# PIC16LF1776 register map
Vendor: Microchip
Registers are 8-bit, read-write, reset 0x0 unless marked. A register's access mark holds for its fields unless they carry their own. Addresses are absolute, and some are shared; only a register's first bit layout is shown; [hi:lo] are bit positions; {n}, {i} and the like mark numbered series; 'fields as' and 'values as' point back to an identical list.

## pwm
0x614 PWM3DCL reset not defined — (power-on value xx------)
  [7:6] DC
0x615 PWM3DCH reset not defined — (power-on value xxxxxxxx)
  [7:0] DC
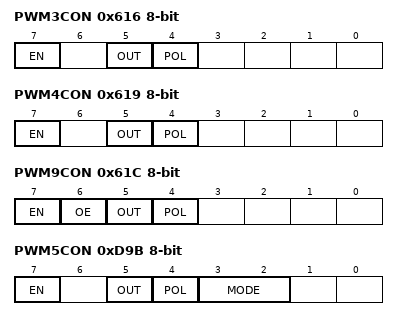
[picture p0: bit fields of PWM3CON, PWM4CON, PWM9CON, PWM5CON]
0x616 PWM3CON
  [7] EN, [5] OUT ro, [4] POL
0x617 PWM4DCL reset not defined — (power-on value xx------)
  [7:6] DC
0x618 PWM4DCH reset not defined — (power-on value xxxxxxxx)
  [7:0] DC
0x619 PWM4CON
  [7] EN, [5] OUT ro, [4] POL
0x61A PWM9DCL reset not defined — (power-on value xx------)
  [7:6] DC
0x61B PWM9DCH reset not defined — (power-on value xxxxxxxx)
  [7:0] DC
0x61C PWM9CON
  [7] EN, [6] OE, [5] OUT ro, [4] POL
0xD91 PWM5PHL reset not defined — 8-bit period timer (power-on value xxxxxxxx)
  [7:0] PH
0xD92 PWM5PHH reset not defined — (power-on value xxxxxxxx)
  [7:0] PH
0xD93 PWM5DCL reset not defined — (power-on value xxxxxxxx)
  [7:0] DC
0xD94 PWM5DCH reset not defined — (power-on value xxxxxxxx)
  [7:0] DC
0xD95 PWM5PRL reset not defined — (power-on value xxxxxxxx)
  [7:0] PR
0xD96 PWM5PRH reset not defined — (power-on value xxxxxxxx)
  [7:0] PR
0xD97 PWM5OFL reset not defined — (power-on value xxxxxxxx)
  [7:0] OF
0xD98 PWM5OFH reset not defined — (power-on value xxxxxxxx)
  [7:0] OF
0xD99 PWM5TMRL
  [7:0] TMR
0xD9A PWM5TMRH
  [7:0] TMR
0xD9B PWM5CON
  [7] EN, [5] OUT ro, [4] POL, [3:2] MODE
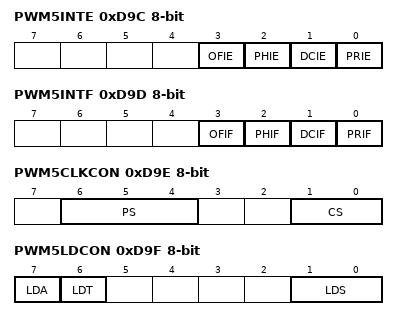
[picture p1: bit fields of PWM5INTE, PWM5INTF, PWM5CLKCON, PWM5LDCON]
0xD9C PWM5INTE
  [3] OFIE, [2] PHIE, [1] DCIE, [0] PRIE
0xD9D PWM5INTF
  [3] OFIF — (can only be cleared)
  [2] PHIF — (can only be cleared)
  [1] DCIF — (can only be cleared)
  [0] PRIF — (can only be cleared)
0xD9E PWM5CLKCON
  [6:4] PS, [1:0] CS
0xD9F PWM5LDCON
  [7] LDA, [6] LDT, [1:0] LDS
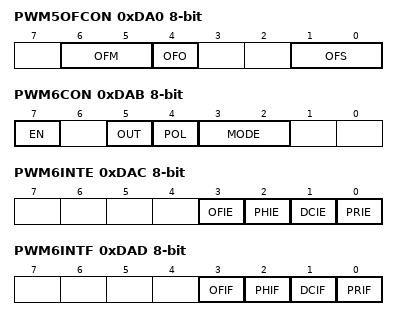
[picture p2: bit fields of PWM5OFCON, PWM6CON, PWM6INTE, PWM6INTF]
0xDA0 PWM5OFCON
  [6:5] OFM, [4] OFO, [1:0] OFS
0xDA1 PWM6PHL reset not defined — 8-bit period timer (power-on value xxxxxxxx)
  [7:0] PH
0xDA2 PWM6PHH reset not defined — (power-on value xxxxxxxx)
  [7:0] PH
0xDA3 PWM6DCL reset not defined — (power-on value xxxxxxxx)
  [7:0] DC
0xDA4 PWM6DCH reset not defined — (power-on value xxxxxxxx)
  [7:0] DC
0xDA5 PWM6PRL reset not defined — (power-on value xxxxxxxx)
  [7:0] PR
0xDA6 PWM6PRH reset not defined — (power-on value xxxxxxxx)
  [7:0] PR
0xDA7 PWM6OFL reset not defined — (power-on value xxxxxxxx)
  [7:0] OF
0xDA8 PWM6OFH reset not defined — (power-on value xxxxxxxx)
  [7:0] OF
0xDA9 PWM6TMRL
  [7:0] TMR
0xDAA PWM6TMRH
  [7:0] TMR
0xDAB PWM6CON
  [7] EN, [5] OUT ro, [4] POL, [3:2] MODE
0xDAC PWM6INTE
  [3] OFIE, [2] PHIE, [1] DCIE, [0] PRIE
0xDAD PWM6INTF
  fields as PWM5INTF
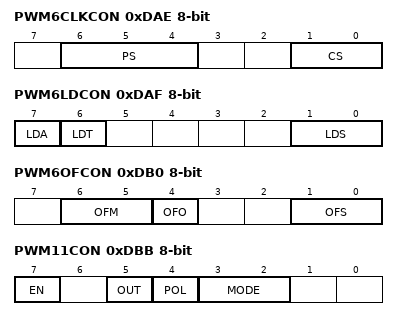
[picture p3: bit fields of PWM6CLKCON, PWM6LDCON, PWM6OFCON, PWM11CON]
0xDAE PWM6CLKCON
  [6:4] PS, [1:0] CS
0xDAF PWM6LDCON
  [7] LDA, [6] LDT, [1:0] LDS
0xDB0 PWM6OFCON
  [6:5] OFM, [4] OFO, [1:0] OFS
0xDB1 PWM11PHL reset not defined — 8-bit period timer (power-on value xxxxxxxx)
  [7:0] PH
0xDB2 PWM11PHH reset not defined — (power-on value xxxxxxxx)
  [7:0] PH
0xDB3 PWM11DCL reset not defined — (power-on value xxxxxxxx)
  [7:0] DC
0xDB4 PWM11DCH reset not defined — (power-on value xxxxxxxx)
  [7:0] DC
0xDB5 PWM11PRL reset not defined — (power-on value xxxxxxxx)
  [7:0] PR
0xDB6 PWM11PRH reset not defined — (power-on value xxxxxxxx)
  [7:0] PR
0xDB7 PWM11OFL reset not defined — (power-on value xxxxxxxx)
  [7:0] OF
0xDB8 PWM11OFH reset not defined — (power-on value xxxxxxxx)
  [7:0] OF
0xDB9 PWM11TMRL
  [7:0] TMR
0xDBA PWM11TMRH
  [7:0] TMR
0xDBB PWM11CON
  [7] EN, [5] OUT ro, [4] POL, [3:2] MODE
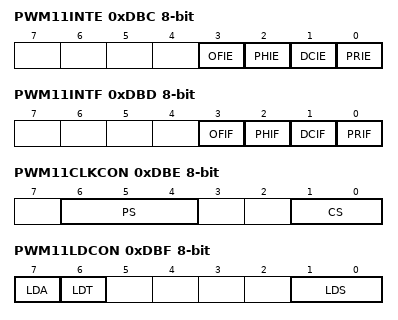
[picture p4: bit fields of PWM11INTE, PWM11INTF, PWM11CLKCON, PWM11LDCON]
0xDBC PWM11INTE
  [3] OFIE, [2] PHIE, [1] DCIE, [0] PRIE
0xDBD PWM11INTF
  fields as PWM5INTF
0xDBE PWM11CLKCON
  [6:4] PS, [1:0] CS
0xDBF PWM11LDCON
  [7] LDA, [6] LDT, [1:0] LDS
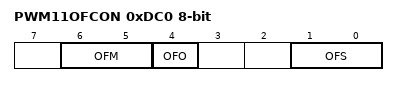
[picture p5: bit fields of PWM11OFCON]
0xDC0 PWM11OFCON
  [6:5] OFM, [4] OFO, [1:0] OFS

## pwm_cog
0x68D COG1PHR
  [5:0] PHR
0x68E COG1PHF
  [5:0] PHF
0x68F COG1BLKR
  [5:0] BLKR
0x690 COG1BLKF
  [5:0] BLKF
0x691 COG1DBR
  [5:0] DBR
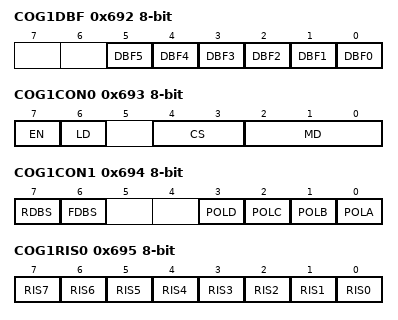
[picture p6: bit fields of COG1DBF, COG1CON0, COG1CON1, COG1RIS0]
0x692 COG1DBF
  [n] DBF{n} (n=0..5)
0x693 COG1CON0
  [7] EN, [6] LD, [4:3] CS, [2:0] MD
0x694 COG1CON1
  [7] RDBS, [6] FDBS, [3] POLD, [2] POLC, [1] POLB, [0] POLA
0x695 COG1RIS0
  [n] RIS{n} (n=0..7)
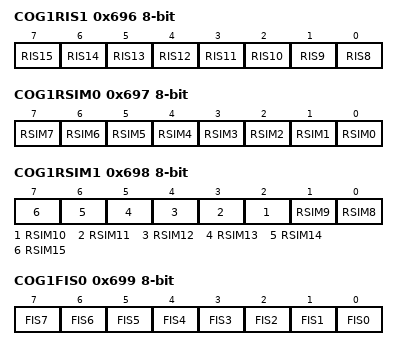
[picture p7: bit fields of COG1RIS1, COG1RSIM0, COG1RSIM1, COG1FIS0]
0x696 COG1RIS1
  [n-8] RIS{n} (n=8..15)
0x697 COG1RSIM0
  [n] RSIM{n} (n=0..7)
0x698 COG1RSIM1
  [n-8] RSIM{n} (n=8..15)
0x699 COG1FIS0
  [n] FIS{n} (n=0..7)
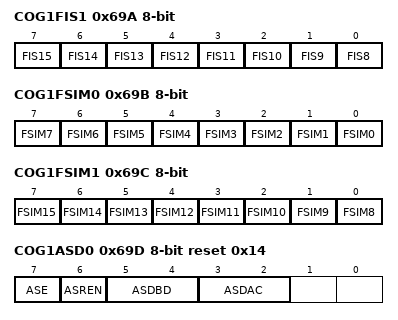
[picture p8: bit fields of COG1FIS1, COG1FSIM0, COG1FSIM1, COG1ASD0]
0x69A COG1FIS1
  [n-8] FIS{n} (n=8..15)
0x69B COG1FSIM0
  [n] FSIM{n} (n=0..7)
0x69C COG1FSIM1
  [n-8] FSIM{n} (n=8..15)
0x69D COG1ASD0 reset 0x14
  [7] ASE, [6] ASREN, [5:4] ASDBD, [3:2] ASDAC
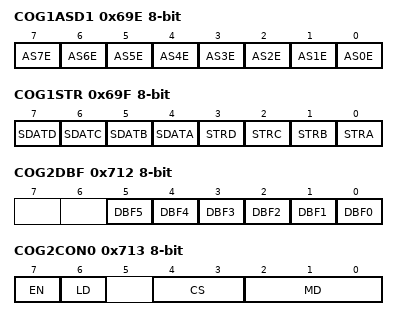
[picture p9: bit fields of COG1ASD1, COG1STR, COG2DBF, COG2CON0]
0x69E COG1ASD1
  [n] AS{n}E (n=0..7)
0x69F COG1STR
  [7] SDATD, [6] SDATC, [5] SDATB, [4] SDATA, [3] STRD, [2] STRC, [1] STRB, [0] STRA
0x70D COG2PHR
  [5:0] PHR
0x70E COG2PHF
  [5:0] PHF
0x70F COG2BLKR
  [5:0] BLKR
0x710 COG2BLKF
  [5:0] BLKF
0x711 COG2DBR
  [5:0] DBR
0x712 COG2DBF
  [n] DBF{n} (n=0..5)
0x713 COG2CON0
  [7] EN, [6] LD, [4:3] CS, [2:0] MD
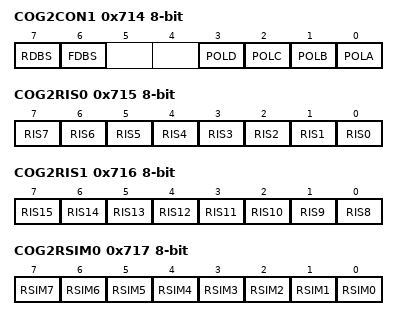
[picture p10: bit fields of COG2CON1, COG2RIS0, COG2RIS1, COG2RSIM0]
0x714 COG2CON1
  [7] RDBS, [6] FDBS, [3] POLD, [2] POLC, [1] POLB, [0] POLA
0x715 COG2RIS0
  [n] RIS{n} (n=0..7)
0x716 COG2RIS1
  [n-8] RIS{n} (n=8..15)
0x717 COG2RSIM0
  [n] RSIM{n} (n=0..7)
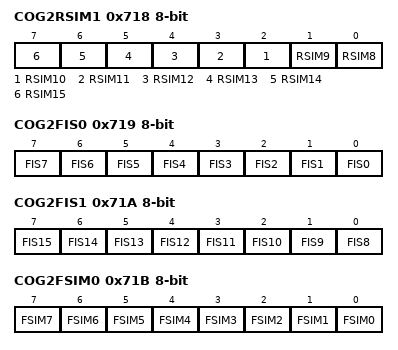
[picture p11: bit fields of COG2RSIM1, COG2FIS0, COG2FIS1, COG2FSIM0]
0x718 COG2RSIM1
  [n-8] RSIM{n} (n=8..15)
0x719 COG2FIS0
  [n] FIS{n} (n=0..7)
0x71A COG2FIS1
  [n-8] FIS{n} (n=8..15)
0x71B COG2FSIM0
  [n] FSIM{n} (n=0..7)
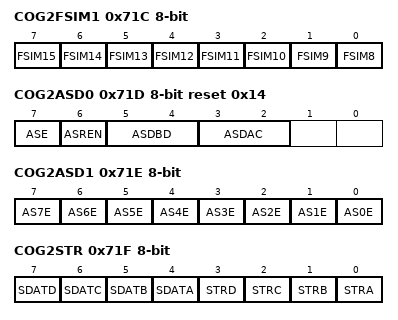
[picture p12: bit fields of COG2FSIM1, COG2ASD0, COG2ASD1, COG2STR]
0x71C COG2FSIM1
  [n-8] FSIM{n} (n=8..15)
0x71D COG2ASD0 reset 0x14
  [7] ASE, [6] ASREN, [5:4] ASDBD, [3:2] ASDAC
0x71E COG2ASD1
  [n] AS{n}E (n=0..7)
0x71F COG2STR
  fields as COG1STR
0x80D COG3PHR
  [5:0] PHR
0x80E COG3PHF
  [5:0] PHF
0x80F COG3BLKR
  [5:0] BLKR
0x810 COG3BLKF
  [5:0] BLKF
0x811 COG3DBR
  [5:0] DBR
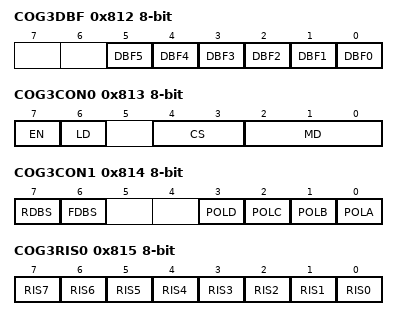
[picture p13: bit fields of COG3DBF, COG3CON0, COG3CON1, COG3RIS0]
0x812 COG3DBF
  [n] DBF{n} (n=0..5)
0x813 COG3CON0
  [7] EN, [6] LD, [4:3] CS, [2:0] MD
0x814 COG3CON1
  [7] RDBS, [6] FDBS, [3] POLD, [2] POLC, [1] POLB, [0] POLA
0x815 COG3RIS0
  [n] RIS{n} (n=0..7)
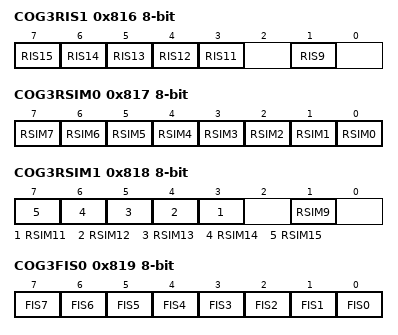
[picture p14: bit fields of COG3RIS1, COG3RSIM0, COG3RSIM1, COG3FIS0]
0x816 COG3RIS1
  [n-8] RIS{n} (n=11..15), [1] RIS9
0x817 COG3RSIM0
  [n] RSIM{n} (n=0..7)
0x818 COG3RSIM1
  [n-8] RSIM{n} (n=11..15), [1] RSIM9
0x819 COG3FIS0
  [n] FIS{n} (n=0..7)
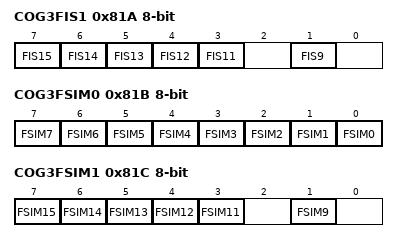
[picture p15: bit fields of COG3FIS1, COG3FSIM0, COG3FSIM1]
0x81A COG3FIS1
  [n-8] FIS{n} (n=11..15), [1] FIS9
0x81B COG3FSIM0
  [n] FSIM{n} (n=0..7)
0x81C COG3FSIM1
  [n-8] FSIM{n} (n=11..15), [1] FSIM9
0x81D COG3ASD0 reset 0x14
  [7] ASE, [6] ASREN, [5:4] ASDBD, [3:2] ASDAC
0x81E COG3ASD1
  [n] AS{n}E (n=0..7)
0x81F COG3STR
  fields as COG1STR

## amp_sloperamp_ctrl
{0x788+6i} PRG{i}RTSS (i=1..3)
  [3:0] RTSS
{0x789+6i} PRG{i}FTSS (i=1..3)
  [3:0] FTSS
{0x78A+6i} PRG{i}INS (i=1..3)
  [3:0] INS
{0x78B+6i} PRG{i}CON0 (i=1..3)
  [7] EN, [5] FEDG, [4] REDG, [3:2] MODE, [1] OS, [0] GO
{0x78C+6i} PRG{i}CON1 (i=1..3)
  [2] RDY ro, [1] FPOL, [0] RPOL
{0x78D+6i} PRG{i}CON2 (i=1..3)
  [4:0] ISET

## CLC
{0xF06+0xA*i} CLC{i}CON (i=1..4) — Configurable logic cell control
  [7] LC{i}EN, [5] LC{i}OUT ro, [4] LC{i}INTP, [3] LC{i}INTN, [2:0] LC{i}MODE
{0xF07+0xA*i} CLC{i}POL reset not defined (i=1..4) — Polarity control (power-on value 0---xxxx)
  [7] LC{i}POL, [n-1] LC{i}G{n}POL (n=1..4)
{0xF08+0xA*i} CLC{i}SEL0 reset not defined (i=1..4) — Input select register 1 (power-on value --xxxxxx)
  [n] LC{i}D1S{n} (n=0..5)
{0xF09+0xA*i} CLC{i}SEL1 reset not defined (i=1..4) — Input select register 1 (power-on value --xxxxxx)
  [n] LC{i}D2S{n} (n=0..5)
{0xF0A+0xA*i} CLC{i}SEL2 reset not defined (i=1..4) — Input select register 2 (power-on value --xxxxxx)
  [n] LC{i}D3S{n} (n=0..5)
{0xF0B+0xA*i} CLC{i}SEL3 reset not defined (i=1..4) — Input select register 3 (power-on value --xxxxxx)
  [n] LC{i}D4S{n} (n=0..5)
{0xF0C+0xA*i} CLC{i}GLS0 reset not defined (i=1..4) — Gate logic select register 0 (power-on value xxxxxxxx)
  [2n-1] LC{i}G1D{n}T (n=1..4), [2n-2] LC{i}G1D{n}N (n=1..4)
{0xF0D+0xA*i} CLC{i}GLS1 reset not defined (i=1..4) — Gate logic select register 1 (power-on value xxxxxxxx)
  [2n-1] LC{i}G2D{n}T (n=1..4), [2n-2] LC{i}G2D{n}N (n=1..4)
{0xF0E+0xA*i} CLC{i}GLS2 reset not defined (i=1..4) — Gate logic select register 2 (power-on value xxxxxxxx)
  [2n-1] LC{i}G3D{n}T (n=1..4), [2n-2] LC{i}G3D{n}N (n=1..4)
{0xF0F+0xA*i} CLC{i}GLS3 reset not defined (i=1..4) — Gate logic select register 3 (power-on value xxxxxxxx)
  [2n-1] LC{i}G4D{n}T (n=1..4), [2n-2] LC{i}G4D{n}N (n=1..4)
